# RN821X_RN721X_SOC_D register map
File version: v1.0.6
CPU: CM0 r0p0, little endian, no MPU, no FPU, 3 interrupt priority bits
Registers are 32-bit, read-write, reset 0x0 unless marked. A register's access mark holds for its fields unless they carry their own. Offsets are from the block's base; [hi:lo] are bit positions; {n}, {i} and the like mark numbered series; 'fields as' and 'values as' point back to an identical list.

## SYSCTL — system control
Base 0x40034000
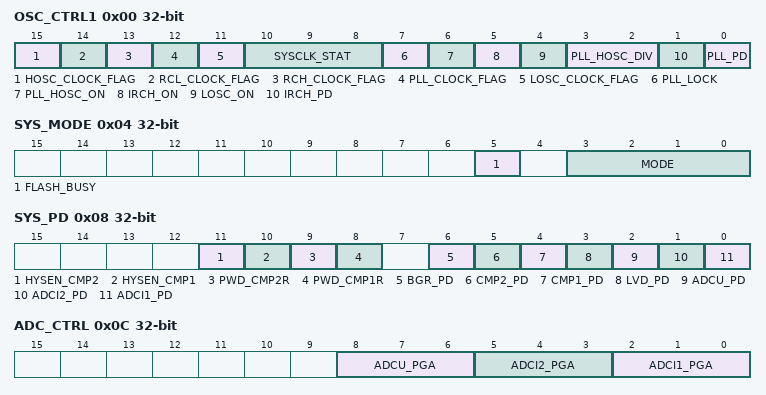
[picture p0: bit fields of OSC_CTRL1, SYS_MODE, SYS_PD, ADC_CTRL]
0x00 OSC_CTRL1 — system oscillator control register No.1
  [15] HOSC_CLOCK_FLAG ro — HOSC ON status flag
    0=OFF (clock off); 1=ON (clock on)
  [14] RCL_CLOCK_FLAG ro — internal RCL ON status flag
    0=OFF (clock off); 1=ON (clock on)
  [13] RCH_CLOCK_FLAG ro — internal RCH ON status flag
    0=OFF (clock off); 1=ON (clock on)
  [12] PLL_CLOCK_FLAG ro — PLL ON status flag
    0=OFF (clock off); 1=ON (clock on)
  [11] LOSC_CLOCK_FLAG ro — LOSC ON status flag
    0=OFF (clock off); 1=ON (clock on)
  [10:8] SYSCLK_STAT ro — system clock freq status flag
    0=7M4 (current system clock freq = 7.3728MHz); 1=3M6 (current system clock freq = 3.6864MHz); 2=1M8 (current system clock freq = 1.8432MHz); 3=32K (current system clock freq = 32.768KHz); 4=14M7 (current system clock freq = 14.7456Mhz); 5=29M5 (current system clock freq = 29.4912Mhz)
  [7] PLL_LOCK ro — PLL locked flag
    0=NUL (PLL hasn't locked yet); 1=LOCK (PLL locked)
  [6] PLL_HOSC_ON ro — system clock flag of external high-frequence oscillator or internal PLL
    0=NUL (PLL_HOSC isn't used as system clock); 1=SYS_CLK (PLL_HOSC used as system clock)
  [5] IRCH_ON ro — system clock flag of internal RC oscillator
    0=NUL (IRCH isn't used as system clock); 1=SYS_CLK (IRCH used as system clock)
  [4] LOSC_ON ro — system clock flag of losc or RCL
    0=NUL (losc isn't used as system clock); 1=SYS_CLK (losc used as system clock)
  [3:2] PLL_HOSC_DIV — system clock division(applicable for high frequency mode(PLL or HOSC))
    0=DIV1 (when PLL/HOSC selected as system clock not divided); 1=DIV2 (when PLL/HOSC selected as system clock divided by 2); 2=DIV4 (when PLL/HOSC selected as system clock divided by 4); 3=DIV8 (when PLL/HOSC selected as system clock divided by 8)
  [1] IRCH_PD — internal RCH oscillator disable bit (=1 disable, =0 enable)
    1=DIS (disable); 0=EN (enable)
  [0] PLL_PD — PLL disable bit (=1 disable, =0 enable)
    1=DIS (disable); 0=EN (enable)
0x04 SYS_MODE — system mode control register
  [5] FLASH_BUSY ro — FLASH busy status flag (=1 busy, =0 idle)
    0=IDLE; 1=BUSY (idle)
  [3:0] MODE — system clock configuration bits
    13=HCM (select HCM mode as system mode); 14=RCM (select RCM mode as system mode); 15=LCM (select LCM mode as system mode)
0x08 SYS_PD — system power-down control register
  [11] HYSEN_CMP2 — CMP2 hysteresis switch bit
    1=ON (switch on); 0=OFF (switch off)
  [10] HYSEN_CMP1 — CMP1 hysteresis switch bit
    1=ON (switch on); 0=OFF (switch off)
  [9] PWD_CMP2R — switch bit of CMP2 internal simpling resistor(=1 register off, =0 register on)
    0=ON (switch on); 1=OFF (switch off)
  [8] PWD_CMP1R — switch bit of CMP1 internal simpling resistor(=1 register off, =0 register on)
    0=ON (switch on); 1=OFF (switch off)
  [6] BGR_PD — BGR power down switch bit(=1 power down, =0 power on)
    0=ON (power on); 1=OFF (power off)
  [5] CMP2_PD — power down switch bit of Comparator No.2 (=1 power down, =0 power on)
    0=ON (power on); 1=OFF (power off)
  [4] CMP1_PD — power down switch bit of Comparator No.1 (=1 power down, =0 power on)
    0=ON (power on); 1=OFF (power off)
  [3] LVD_PD — LVD power down switch bit(=1 power down, =0 power on)
    0=ON (power on); 1=OFF (power off)
  [2] ADCU_PD — U ADC power down switch bit(=1 power down, =0 power on)
    0=ON (power on); 1=OFF (power off)
  [1] ADCI2_PD — I2 ADC power down switch bit(=1 power down, =0 power on)
    0=ON (power on); 1=OFF (power off)
  [0] ADCI1_PD — I1 ADC power down switch bit(=1 power down, =0 power on)
    0=ON (power on); 1=OFF (power off)
0x0C ADC_CTRL — ADC control register
  [8:6] ADCU_PGA — ADC U PGA config bits
    0=1TIME (PGA config 1 time); 1=2TIME (PGA config 2 times); 2=4TIME (PGA config 4 times)
  [5:3] ADCI2_PGA — ADC I2 PGA config bits
    values as ADCU_PGA
  [2:0] ADCI1_PGA — ADC I1 PGA config bits
    0=1TIME (PGA config 1 time); 1=2TIME (PGA config 2 times); 2=8TIME (PGA config 8 times); 3=16TIME (PGA config 16 times)
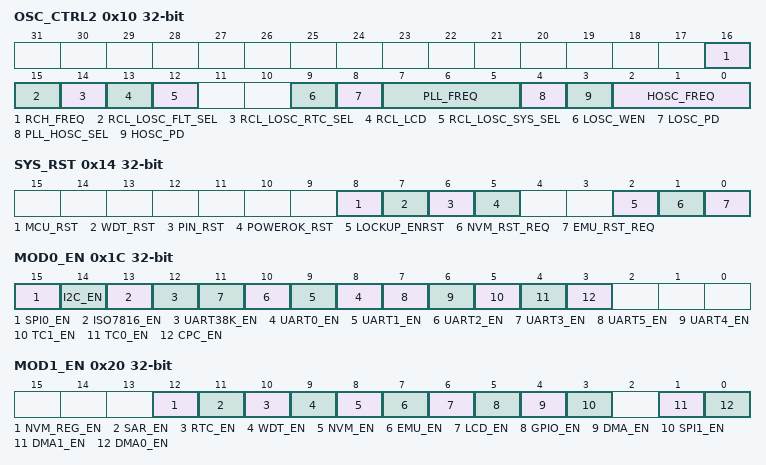
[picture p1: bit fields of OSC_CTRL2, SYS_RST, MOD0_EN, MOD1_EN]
0x10 OSC_CTRL2 — system oscillator control No.2
  [16] RCH_FREQ — RCH frequency selection bits
    0=1M6 (internal RCH freq select 1.6MHz); 1=3M2 (internal RCH freq select 3.2MHz)
  [15] RCL_LOSC_FLT_SEL — clock selection bit (RCL/LOSC) for KBI filter
    0=LOSC (select LOSC); 1=RCL (select RCL)
  [14] RCL_LOSC_RTC_SEL — clock selection bit (RCL/LOSC) for RTC
    0=LOSC (select LOSC); 1=RCL (select RCL)
  [13] RCL_LCD — clock selection bit (RCL/LOSC) for LCD
    0=LOSC (select LOSC); 1=RCL (select RCL)
  [12] RCL_LOSC_SYS_SEL — system clock selection bit for low frequency mode
    0=LOSC (select LOSC); 1=RCL (select RCL)
  [9] LOSC_WEN — LOSC_PD writable enable/disable bit
    0=DIS (LOSC_PD write disable); 1=EN (LOSC_PD write enable)
  [8] LOSC_PD — LOSC power down switch bit
    0=ON (power on); 1=OFF (power off)
  [7:5] PLL_FREQ — PLL freq selection bits
    0=7M4 (PLL freq select 7.3728MHz); 1=14M7 (PLL freq select 14.7456Mhz)
  [4] PLL_HOSC_SEL — system clock selection bits for full speed mode
    0=PLL (select PLL as system clock); 1=HOSC (select HOSC as system clock)
  [3] HOSC_PD — HOSC disable bit (=1 disable HOSC, =0 enable HOSC)
    0=ON (power on); 1=OFF (power off)
  [2:0] HOSC_FREQ — freq of external high-frequence oscillator select bits
    0=7M4 (external high-frequence oscillator freq = 7.3728MHz); 1=14M7 (external high-frequence oscillator freq = 14.7456Mhz); 3=29M5_PLUS (external high-frequence oscillator freq = 29.4912Mhz (driver enhanced))
0x14 SYS_RST — system reset register
  [8] MCU_RST write-1-clears — CPU reset flag(software or LOCKUP) (=1 reset occured)
    1=OCC (reset occured); 0=NUL (reset not occured)
  [7] WDT_RST write-1-clears — WDT reset flag (=1 reset occurd)
    1=OCC (reset occured); 0=NUL (reset not occured)
  [6] PIN_RST write-1-clears — external pin reset flag (=1 reet occured)
    1=OCC (reset occured); 0=NUL (reset not occured)
  [5] POWEROK_RST write-1-clears — power-on reset flag (=1 reset ccured)
    1=OCC (reset occured); 0=NUL (reset not occured)
  [2] LOCKUP_ENRST — selection for the connection of lockup and system reset
    0=DIS (lock up can not cause system reset); 1=EN (lock up cause system reset)
  [1] NVM_RST_REQ — NVM module soft reset cfg bit
    1=EN (enable module soft reset); 0=DIS (disable module soft reset)
  [0] EMU_RST_REQ — EMU module soft reset cfg bit
    values as NVM_RST_REQ
0x18 MAP_CTRL — system control register
  [2:0] REMAP — system remap address configuration bits
    0=FLASH mapped at address 0; 1=FLASH mapped at address 1/2 (2nd FLASH at 0x0, 1st FLASH at 0x4000 and bootload at 0); 2=FLASH switch mapping address with SRAM(FLASH at 0x10000000 and SRAM at 0); 3=BOOTROM mapped at address 0; 4=FLASH mapped at address 1/2 total memory capacity(only support less than 512KB)
0x1C MOD0_EN — module enable register No.0
  [all] fields
    0=DIS (module disabled and clock stop); 1=EN (module enabled and clock start)
  [15] SPI0_EN — SPI0 enable bit
  [14] I2C_EN — I2C enable bit
  [13] ISO7816_EN — ISO7816 enable bit
  [12] UART38K_EN — UART38K enable bit
  [n+8] UART{n}_EN (n=0..3) — UART{n} enable bit
  [7] UART5_EN — UART5 enable bit
  [6] UART4_EN — UART4 enable bit
  [5] TC1_EN — TC1 enable bit
  [4] TC0_EN — TC0 enable bit
  [3] CPC_EN — CPC enable bit
0x20 MOD1_EN — module enable register No.1
  [12] NVM_REG_EN — NVM REG read/write enable bit
    0=DIS (clock stop); 1=EN (clock start)
  [11] SAR_EN — SAR enable bit
    0=DIS (clock stop); 1=EN (clock start)
  [10] RTC_EN — RTC enable bit
    0=DIS (clock stop); 1=EN (clock start)
  [9] WDT_EN — WDT enable bit
    0=DIS (clock stop); 1=EN (clock start)
  [8] NVM_EN — NVM enable bit
    0=DIS (clock stop); 1=EN (clock start)
  [7] EMU_EN — EMU enable bit
    0=DIS (clock stop); 1=EN (clock start)
  [6] LCD_EN — LCD enable bit
    values as the fields of MOD0_EN
  [5] GPIO_EN — GPIO enable bit
    values as the fields of MOD0_EN
  [4] DMA_EN — DMA enable bit
    values as the fields of MOD0_EN
  [3] SPI1_EN — SPI1 enable bit
    values as the fields of MOD0_EN
  [1] DMA1_EN — DMA1 enable bit
    values as the fields of MOD0_EN
  [0] DMA0_EN — DMA0 enable bit
    values as the fields of MOD0_EN
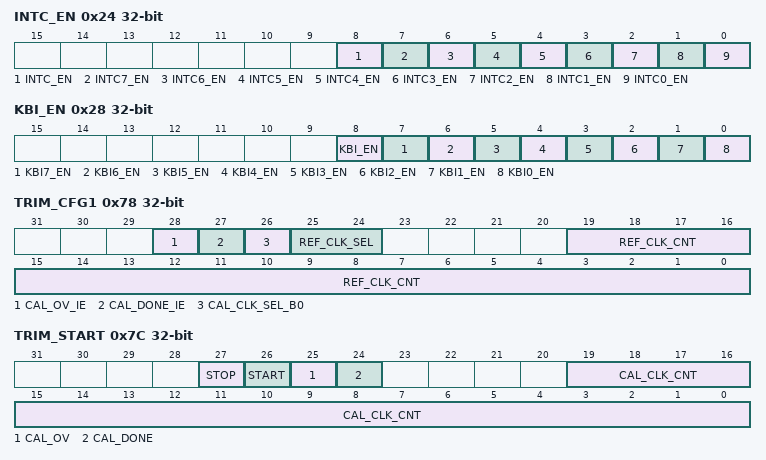
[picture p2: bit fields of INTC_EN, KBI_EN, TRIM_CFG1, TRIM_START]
0x24 INTC_EN — INTC enable register
  [8] INTC_EN — INTC enable bit
  [7] INTC7_EN — INTC channel No.7 enable bit
  [6] INTC6_EN — INTC channel No.6 enable bit
  [5] INTC5_EN — INTC channel No.5 enable bit
    0=DIS (channel disabled and clock stop); 1=EN (channel enabled and clock start)
  [4] INTC4_EN — INTC channel No.4 enable bit
    values as INTC5_EN
  [3] INTC3_EN — INTC channel No.3 enable bit
    values as INTC5_EN
  [2] INTC2_EN — INTC channel No.2 enable bit
    values as INTC5_EN
  [1] INTC1_EN — INTC channel No.1 enable bit
    values as INTC5_EN
  [0] INTC0_EN — INTC channel No.0 enable bit
    values as INTC5_EN
0x28 KBI_EN — KBI enable register
  [8] KBI_EN — KBI clock enable bit
  [7] KBI7_EN — KBI channel No.7 enable bit
    values as INTC_EN.INTC5_EN
  [6] KBI6_EN — KBI channel No.6 enable bit
    values as INTC_EN.INTC5_EN
  [5] KBI5_EN — KBI channel No.5 enable bit
    values as INTC_EN.INTC5_EN
  [4] KBI4_EN — KBI channel No.4 enable bit
    values as INTC_EN.INTC5_EN
  [3] KBI3_EN — KBI channel No.3 enable bit
    values as INTC_EN.INTC5_EN
  [2] KBI2_EN — KBI channel No.2 enable bit
    values as INTC_EN.INTC5_EN
  [1] KBI1_EN — KBI channel No.1 enable bit
    values as INTC_EN.INTC5_EN
  [0] KBI0_EN — KBI channel No.0 enable bit
    values as INTC_EN.INTC5_EN
0x2C CHIP_ID ro
  [15:0] CHIP_ID
0x30 SYS_PS — system control registers write password register
  [7:0] SYS_PSW — system control register set access protection
    130=PS (SYSCTRL registers offset adderess write access enable); 85=DIS (SYSCTRL registers offset adderess write access disable)
0x34 IRFR_CTRL ro — infra-red modulation clock divisor register
  [5:0] IRFR_CTRL — infra-red modulation clock divisor cfg bits
0x78 TRIM_CFG1 — clock trim configuration register No.1
  [28] CAL_OV_IE — calculation overflow interrupt enable bit
    0=DIS (disable interrupt); 1=EN (enable interrupt)
  [27] CAL_DONE_IE — calculation down interrupt enable bit
    0=DIS (disable interrupt); 1=EN (enable interrupt)
  [26] CAL_CLK_SEL_B0 — calculated clock selection bit0
  [25:24] REF_CLK_SEL — reference clock selection bits
    0=LOSC (select LOSC as reference clock); 1=HOSC (select HOSC as reference clock); 2=RCH (select RCH as reference clock)
  [19:0] REF_CLK_CNT — reference clock counter value bits
0x7C TRIM_START — clock trim start register
  [27] STOP — stop bit of clock trim
    0=NUL (no operation); 1=STOP (stop clock trim(cleared auto while counter down))
  [26] START — start bit of clock trim
    0=NUL (no operation); 1=START (start clock trim(cleared auto while counter down))
  [25] CAL_OV — clock trim counter overflow flag
    0=NUL (clock trim counter not overflow); 1=OV (clock trim counter overflow)
  [24] CAL_DONE — clock trim finish flag
    0=NUL (clock trim not finish); 1=DONE (clock trim finish)
  [19:0] CAL_CLK_CNT ro — counter value of the calculated clock
